# DSS_DSS_OVR1_30207000h register map
Vendor: Texas Instruments
Peripheral module from a debugger description file (folder am62L).
Registers are 32-bit, read-write, reset 0x0 unless marked. A register's access mark holds for its fields unless they carry their own. Offsets are as the file gives them; lines under a group give offsets from that group; [hi:lo] are bit positions; {n}, {i} and the like mark numbered series; 'fields as' and 'values as' point back to an identical list; <NAME> marks a mode.

## DSS_OVR1
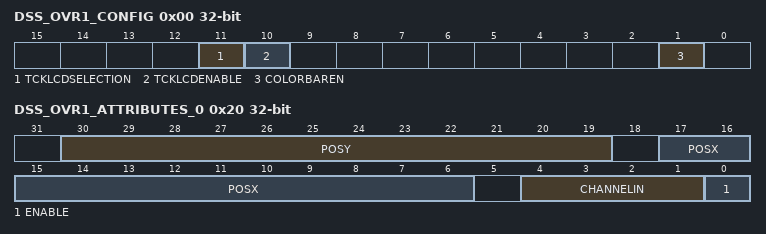
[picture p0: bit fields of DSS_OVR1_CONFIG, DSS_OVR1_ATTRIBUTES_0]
0x00 DSS_OVR1_CONFIG — The control register configures the Display Controller module for the VP output. Shadow register
  [11] TCKLCDSELECTION — Transparency Color Key Selection 0 Destination transparency color key selected1 Source transparency color key selected
  [10] TCKLCDENABLE — Transparency Color Key Enable 0 Disable the transparency color key for the LCD1 Enable the transparency color key for the LCD
  [1] COLORBAREN — Enable the Color-Bar 0 Disabled1 Enabled
0x08 DSS_OVR1_DEFAULT_COLOR — The control register configures the default solid background color LSB[31:0]. Shadow register
  [31:0] DEFAULTCOLOR — 32-bit LSB of ARGB background color
0x0C DSS_OVR1_DEFAULT_COLOR2 — The control register configures the default solid background color MSB[47:32]. Shadow register
  [15:0] DEFAULTCOLOR — 16-bit MSB of ARGB background color
0x10 DSS_OVR1_TRANS_COLOR_MAX — The register sets the max transparency color value for the overlays. Shadow register
  [31:0] TRANSCOLORKEY — LSB[31:0]. Transparency Color Key Value in 36-bit RGB format
0x14 DSS_OVR1_TRANS_COLOR_MAX2 — The register sets the max transparency color value for the overlays. Shadow register
  [3:0] TRANSCOLORKEY — MSB[35:32]. Transparency Color Key Value in 36-bit RGB format
0x18 DSS_OVR1_TRANS_COLOR_MIN — The register sets the min transparency color value for the overlays. Shadow register
  fields as DSS_OVR1_TRANS_COLOR_MAX
0x1C DSS_OVR1_TRANS_COLOR_MIN2 — The register sets the min transparency color value for the overlays. Shadow register
  fields as DSS_OVR1_TRANS_COLOR_MAX2
0x20 DSS_OVR1_ATTRIBUTES_0 — The register configures the attributes of layer-0, ZORDER= 0, of the Overlay manager. Shadow register
  [30:19] POSY — Y position of the layer. Encoded value [from 0 to 4095] to specify the Y position of the layer on the screen. The line at the top has the Y-position 0
  [17:6] POSX — X position of the layer. Encoded value [from 0 to 4095] to specify the X position of the layer on the screen. The first pixel on the left of the screen has the X-position 0
  [4:1] CHANNELIN — Should be written only 1 ;CHANNELIN[3:0]==1, VIDL1 pipeline is selected , other values are reserved 1 VIDL-1 is connected to the layer
  [0] ENABLE — Layer Enable
